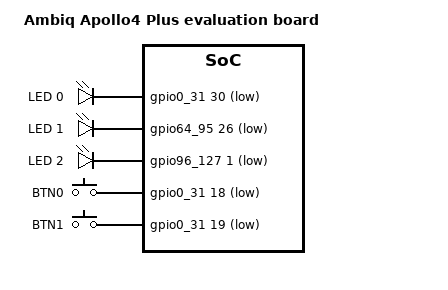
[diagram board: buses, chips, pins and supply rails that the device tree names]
/dts-v1/;
#include <ambiq/ambiq_apollo4p.dtsi>

#include "apollo4p_evb-pinctrl.dtsi"

/ {
	model = "Ambiq Apollo4 Plus evaluation board";
	compatible = "ambiq,apollo4p_evb";

	chosen {
		zephyr,itcm = &tcm;
		zephyr,sram = &sram0;
		zephyr,flash = &flash0;
		zephyr,console = &uart0;
		zephyr,shell-uart = &uart0;
		zephyr,uart-pipe = &uart0;
	};

	aliases {
		watchdog0 = &wdt0;
		led0 = &led0;
		led1 = &led1;
		led2 = &led2;
		sw0 = &button0;
		sw1 = &button1;
	};

	leds {
		compatible = "gpio-leds";
		led0: led_0 {
			gpios = <&gpio0_31 30 (GPIO_PULL_UP | GPIO_ACTIVE_LOW)>;
			label = "LED 0";
		};
		led1: led_1 {
			gpios = <&gpio64_95 26 (GPIO_PULL_UP | GPIO_ACTIVE_LOW)>;
			label = "LED 1";
		};
		led2: led_2 {
			gpios = <&gpio96_127 1 (GPIO_PULL_UP | GPIO_ACTIVE_LOW)>;
			label = "LED 2";
		};
	};

	buttons {
		compatible = "gpio-keys";
		button0: button_0 {
			gpios = <&gpio0_31 18 (GPIO_PULL_UP | GPIO_ACTIVE_LOW)>;
			label = "BTN0";
		};
		button1: button_1 {
			gpios = <&gpio0_31 19 (GPIO_PULL_UP | GPIO_ACTIVE_LOW)>;
			label = "BTN1";
		};
	};
};
